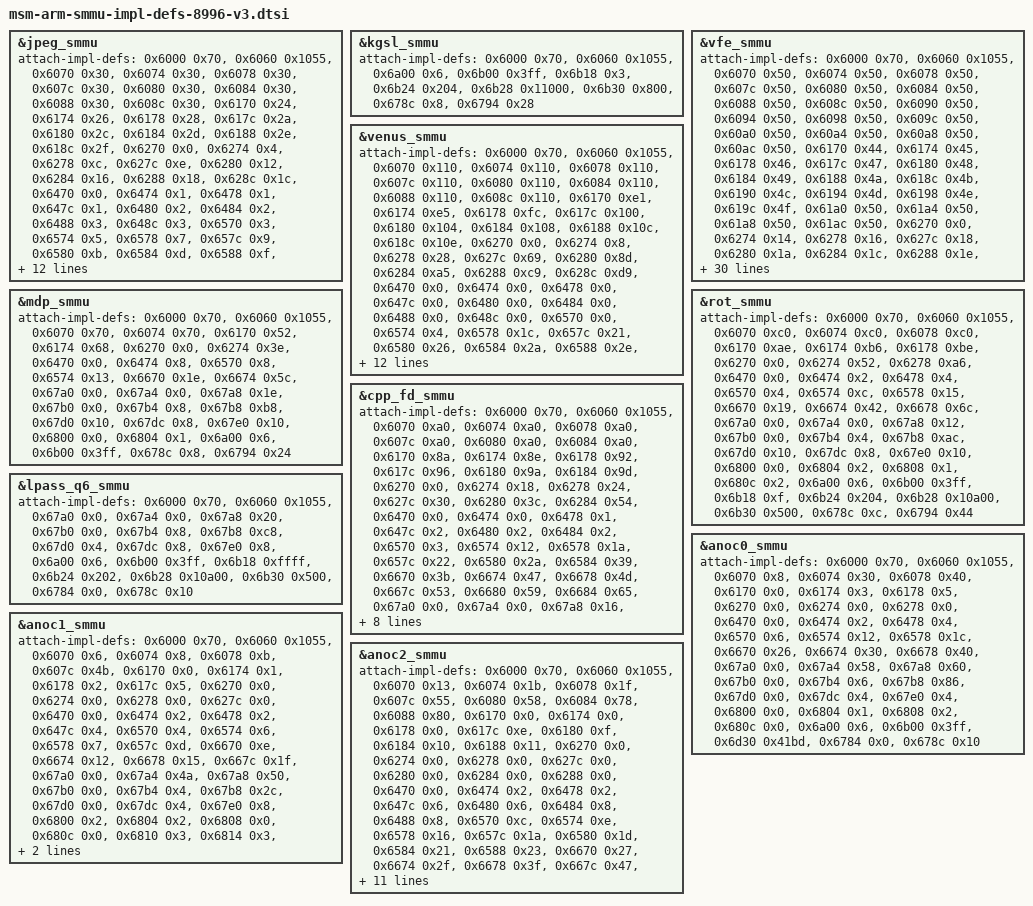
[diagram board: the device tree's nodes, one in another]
/* Copyright (c) 2015, The Linux Foundation. All rights reserved.
 *
 * This program is free software; you can redistribute it and/or modify
 * it under the terms of the GNU General Public License version 2 and
 * only version 2 as published by the Free Software Foundation.
 *
 * This program is distributed in the hope that it will be useful,
 * but WITHOUT ANY WARRANTY; without even the implied warranty of
 * MERCHANTABILITY or FITNESS FOR A PARTICULAR PURPOSE.  See the
 * GNU General Public License for more details.
 */


&jpeg_smmu {
	attach-impl-defs = <0x6000 0x70>,
		<0x6060 0x1055>,
		<0x6070 0x30>,
		<0x6074 0x30>,
		<0x6078 0x30>,
		<0x607c 0x30>,
		<0x6080 0x30>,
		<0x6084 0x30>,
		<0x6088 0x30>,
		<0x608c 0x30>,
		<0x6170 0x24>,
		<0x6174 0x26>,
		<0x6178 0x28>,
		<0x617c 0x2a>,
		<0x6180 0x2c>,
		<0x6184 0x2d>,
		<0x6188 0x2e>,
		<0x618c 0x2f>,
		<0x6270 0x0>,
		<0x6274 0x4>,
		<0x6278 0xc>,
		<0x627c 0xe>,
		<0x6280 0x12>,
		<0x6284 0x16>,
		<0x6288 0x18>,
		<0x628c 0x1c>,
		<0x6470 0x0>,
		<0x6474 0x1>,
		<0x6478 0x1>,
		<0x647c 0x1>,
		<0x6480 0x2>,
		<0x6484 0x2>,
		<0x6488 0x3>,
		<0x648c 0x3>,
		<0x6570 0x3>,
		<0x6574 0x5>,
		<0x6578 0x7>,
		<0x657c 0x9>,
		<0x6580 0xb>,
		<0x6584 0xd>,
		<0x6588 0xf>,
		<0x658c 0x11>,
		<0x6670 0x13>,
		<0x6674 0x16>,
		<0x6678 0x1c>,
		<0x667c 0x1e>,
		<0x6680 0x21>,
		<0x6684 0x24>,
		<0x6688 0x26>,
		<0x668c 0x2a>,
		<0x67a0 0x0>,
		<0x67a4 0x0>,
		<0x67a8 0xc>,
		<0x67b0 0x0>,
		<0x67b4 0x3>,
		<0x67b8 0x83>,
		<0x67d0 0x10>,
		<0x67dc 0x8>,
		<0x67e0 0x10>,
		<0x6800 0x0>,
		<0x6804 0x1>,
		<0x6808 0x2>,
		<0x680c 0x3>,
		<0x6810 0x4>,
		<0x6814 0x5>,
		<0x6818 0x6>,
		<0x681c 0x7>,
		<0x6a00 0x6>,
		<0x6b00 0x3ff>,
		<0x6b18 0xff>,
		<0x6b24 0x204>,
		<0x6b28 0x10800>,
		<0x6b30 0x400>,
		<0x678c 0x6>,
		<0x6794 0x24>;
};

&kgsl_smmu {
	attach-impl-defs = <0x6000 0x70>,
		<0x6060 0x1055>,
		<0x6a00 0x6>,
		<0x6b00 0x3ff>,
		<0x6b18 0x3>,
		<0x6b24 0x204>,
		<0x6b28 0x11000>,
		<0x6b30 0x800>,
		<0x678c 0x8>,
		<0x6794 0x28>;
};

&vfe_smmu {
	attach-impl-defs = <0x6000 0x70>,
		<0x6060 0x1055>,
		<0x6070 0x50>,
		<0x6074 0x50>,
		<0x6078 0x50>,
		<0x607c 0x50>,
		<0x6080 0x50>,
		<0x6084 0x50>,
		<0x6088 0x50>,
		<0x608c 0x50>,
		<0x6090 0x50>,
		<0x6094 0x50>,
		<0x6098 0x50>,
		<0x609c 0x50>,
		<0x60a0 0x50>,
		<0x60a4 0x50>,
		<0x60a8 0x50>,
		<0x60ac 0x50>,
		<0x6170 0x44>,
		<0x6174 0x45>,
		<0x6178 0x46>,
		<0x617c 0x47>,
		<0x6180 0x48>,
		<0x6184 0x49>,
		<0x6188 0x4a>,
		<0x618c 0x4b>,
		<0x6190 0x4c>,
		<0x6194 0x4d>,
		<0x6198 0x4e>,
		<0x619c 0x4f>,
		<0x61a0 0x50>,
		<0x61a4 0x50>,
		<0x61a8 0x50>,
		<0x61ac 0x50>,
		<0x6270 0x0>,
		<0x6274 0x14>,
		<0x6278 0x16>,
		<0x627c 0x18>,
		<0x6280 0x1a>,
		<0x6284 0x1c>,
		<0x6288 0x1e>,
		<0x628c 0x20>,
		<0x6290 0x22>,
		<0x6294 0x36>,
		<0x6298 0x38>,
		<0x629c 0x3a>,
		<0x62a0 0x3c>,
		<0x62a4 0x3e>,
		<0x62a8 0x40>,
		<0x62ac 0x42>,
		<0x6470 0x0>,
		<0x6474 0x1>,
		<0x6478 0x2>,
		<0x647c 0x3>,
		<0x6480 0x4>,
		<0x6484 0x4>,
		<0x6488 0x4>,
		<0x648c 0x4>,
		<0x6490 0x4>,
		<0x6494 0x5>,
		<0x6498 0x6>,
		<0x649c 0x7>,
		<0x64a0 0x8>,
		<0x64a4 0x8>,
		<0x64a8 0x8>,
		<0x64ac 0x8>,
		<0x6570 0x8>,
		<0x6574 0xb>,
		<0x6578 0xe>,
		<0x657c 0x11>,
		<0x6580 0x13>,
		<0x6584 0x15>,
		<0x6588 0x17>,
		<0x658c 0x19>,
		<0x6590 0x1b>,
		<0x6594 0x1e>,
		<0x6598 0x21>,
		<0x659c 0x24>,
		<0x65a0 0x26>,
		<0x65a4 0x28>,
		<0x65a8 0x2a>,
		<0x65ac 0x2c>,
		<0x6670 0x2e>,
		<0x6674 0x38>,
		<0x6678 0x39>,
		<0x667c 0x3a>,
		<0x6680 0x3b>,
		<0x6684 0x3c>,
		<0x6688 0x3d>,
		<0x668c 0x3e>,
		<0x6690 0x3f>,
		<0x6694 0x49>,
		<0x6698 0x4a>,
		<0x669c 0x4b>,
		<0x66a0 0x4c>,
		<0x66a4 0x4d>,
		<0x66a8 0x4e>,
		<0x66ac 0x4f>,
		<0x67a0 0x0>,
		<0x67a4 0x0>,
		<0x67a8 0xc>,
		<0x67b0 0x0>,
		<0x67b4 0x8>,
		<0x67b8 0x138>,
		<0x67d0 0x10>,
		<0x67dc 0x8>,
		<0x67e0 0x10>,
		<0x6800 0x0>,
		<0x6804 0x1>,
		<0x6808 0x2>,
		<0x680c 0x3>,
		<0x6810 0x4>,
		<0x6814 0x5>,
		<0x6818 0x6>,
		<0x681c 0x7>,
		<0x6820 0x8>,
		<0x6824 0x9>,
		<0x6828 0xa>,
		<0x682c 0xb>,
		<0x6830 0xc>,
		<0x6834 0xd>,
		<0x6838 0xe>,
		<0x683c 0xf>,
		<0x6a00 0x6>,
		<0x6b00 0x3ff>,
		<0x6b18 0xffff>,
		<0x6b24 0x204>,
		<0x6b28 0x10a00>,
		<0x6b30 0x500>,
		<0x678c 0xb>,
		<0x6794 0x2f>;
};

&venus_smmu {
	attach-impl-defs = <0x6000 0x70>,
		<0x6060 0x1055>,
		<0x6070 0x110>,
		<0x6074 0x110>,
		<0x6078 0x110>,
		<0x607c 0x110>,
		<0x6080 0x110>,
		<0x6084 0x110>,
		<0x6088 0x110>,
		<0x608c 0x110>,
		<0x6170 0xe1>,
		<0x6174 0xe5>,
		<0x6178 0xfc>,
		<0x617c 0x100>,
		<0x6180 0x104>,
		<0x6184 0x108>,
		<0x6188 0x10c>,
		<0x618c 0x10e>,
		<0x6270 0x0>,
		<0x6274 0x8>,
		<0x6278 0x28>,
		<0x627c 0x69>,
		<0x6280 0x8d>,
		<0x6284 0xa5>,
		<0x6288 0xc9>,
		<0x628c 0xd9>,
		<0x6470 0x0>,
		<0x6474 0x0>,
		<0x6478 0x0>,
		<0x647c 0x0>,
		<0x6480 0x0>,
		<0x6484 0x0>,
		<0x6488 0x0>,
		<0x648c 0x0>,
		<0x6570 0x0>,
		<0x6574 0x4>,
		<0x6578 0x1c>,
		<0x657c 0x21>,
		<0x6580 0x26>,
		<0x6584 0x2a>,
		<0x6588 0x2e>,
		<0x658c 0x30>,
		<0x6670 0x32>,
		<0x6674 0x36>,
		<0x6678 0x46>,
		<0x667c 0x58>,
		<0x6680 0x62>,
		<0x6684 0x6d>,
		<0x6688 0x75>,
		<0x668c 0x7d>,
		<0x67a0 0x0>,
		<0x67a4 0x0>,
		<0x67a8 0x2f>,
		<0x67b0 0x0>,
		<0x67b4 0x0>,
		<0x67b8 0x190>,
		<0x67d0 0x8>,
		<0x67dc 0x8>,
		<0x67e0 0x8>,
		<0x6800 0x0>,
		<0x6804 0x1>,
		<0x6808 0x2>,
		<0x680c 0x3>,
		<0x6810 0x4>,
		<0x6814 0x5>,
		<0x6818 0x6>,
		<0x681c 0x7>,
		<0x6a00 0x6>,
		<0x6b00 0x3ff>,
		<0x6b18 0xff>,
		<0x6b24 0x203>,
		<0x6b28 0x10a00>,
		<0x6b30 0x500>,
		<0x678c 0x18>,
		<0x6794 0x43>;
};

&mdp_smmu {
	attach-impl-defs = <0x6000 0x70>,
		<0x6060 0x1055>,
		<0x6070 0x70>,
		<0x6074 0x70>,
		<0x6170 0x52>,
		<0x6174 0x68>,
		<0x6270 0x0>,
		<0x6274 0x3e>,
		<0x6470 0x0>,
		<0x6474 0x8>,
		<0x6570 0x8>,
		<0x6574 0x13>,
		<0x6670 0x1e>,
		<0x6674 0x5c>,
		<0x67a0 0x0>,
		<0x67a4 0x0>,
		<0x67a8 0x1e>,
		<0x67b0 0x0>,
		<0x67b4 0x8>,
		<0x67b8 0xb8>,
		<0x67d0 0x10>,
		<0x67dc 0x8>,
		<0x67e0 0x10>,
		<0x6800 0x0>,
		<0x6804 0x1>,
		<0x6a00 0x6>,
		<0x6b00 0x3ff>,
		<0x678c 0x8>,
		<0x6794 0x24>;
};

&rot_smmu {
	attach-impl-defs = <0x6000 0x70>,
		<0x6060 0x1055>,
		<0x6070 0xc0>,
		<0x6074 0xc0>,
		<0x6078 0xc0>,
		<0x6170 0xae>,
		<0x6174 0xb6>,
		<0x6178 0xbe>,
		<0x6270 0x0>,
		<0x6274 0x52>,
		<0x6278 0xa6>,
		<0x6470 0x0>,
		<0x6474 0x2>,
		<0x6478 0x4>,
		<0x6570 0x4>,
		<0x6574 0xc>,
		<0x6578 0x15>,
		<0x6670 0x19>,
		<0x6674 0x42>,
		<0x6678 0x6c>,
		<0x67a0 0x0>,
		<0x67a4 0x0>,
		<0x67a8 0x12>,
		<0x67b0 0x0>,
		<0x67b4 0x4>,
		<0x67b8 0xac>,
		<0x67d0 0x10>,
		<0x67dc 0x8>,
		<0x67e0 0x10>,
		<0x6800 0x0>,
		<0x6804 0x2>,
		<0x6808 0x1>,
		<0x680c 0x2>,
		<0x6a00 0x6>,
		<0x6b00 0x3ff>,
		<0x6b18 0xf>,
		<0x6b24 0x204>,
		<0x6b28 0x10a00>,
		<0x6b30 0x500>,
		<0x678c 0xc>,
		<0x6794 0x44>;
};

&cpp_fd_smmu {
	attach-impl-defs = <0x6000 0x70>,
		<0x6060 0x1055>,
		<0x6070 0xa0>,
		<0x6074 0xa0>,
		<0x6078 0xa0>,
		<0x607c 0xa0>,
		<0x6080 0xa0>,
		<0x6084 0xa0>,
		<0x6170 0x8a>,
		<0x6174 0x8e>,
		<0x6178 0x92>,
		<0x617c 0x96>,
		<0x6180 0x9a>,
		<0x6184 0x9d>,
		<0x6270 0x0>,
		<0x6274 0x18>,
		<0x6278 0x24>,
		<0x627c 0x30>,
		<0x6280 0x3c>,
		<0x6284 0x54>,
		<0x6470 0x0>,
		<0x6474 0x0>,
		<0x6478 0x1>,
		<0x647c 0x2>,
		<0x6480 0x2>,
		<0x6484 0x2>,
		<0x6570 0x3>,
		<0x6574 0x12>,
		<0x6578 0x1a>,
		<0x657c 0x22>,
		<0x6580 0x2a>,
		<0x6584 0x39>,
		<0x6670 0x3b>,
		<0x6674 0x47>,
		<0x6678 0x4d>,
		<0x667c 0x53>,
		<0x6680 0x59>,
		<0x6684 0x65>,
		<0x67a0 0x0>,
		<0x67a4 0x0>,
		<0x67a8 0x16>,
		<0x67b0 0x0>,
		<0x67b4 0x3>,
		<0x67b8 0x1c3>,
		<0x67d0 0x10>,
		<0x67dc 0x8>,
		<0x67e0 0x10>,
		<0x6800 0x0>,
		<0x6804 0x1>,
		<0x6808 0x2>,
		<0x680c 0x3>,
		<0x6810 0x4>,
		<0x6814 0x5>,
		<0x6818 0x0>,
		<0x681c 0x0>,
		<0x6a00 0x6>,
		<0x6b00 0x3ff>,
		<0x6b18 0xff>,
		<0x6b24 0x204>,
		<0x6b28 0x10a00>,
		<0x6b30 0x500>,
		<0x678c 0x8>,
		<0x6794 0x2f>;
};

&lpass_q6_smmu {
	attach-impl-defs = <0x6000 0x70>,
		<0x6060 0x1055>,
		<0x67a0 0x0>,
		<0x67a4 0x0>,
		<0x67a8 0x20>,
		<0x67b0 0x0>,
		<0x67b4 0x8>,
		<0x67b8 0xc8>,
		<0x67d0 0x4>,
		<0x67dc 0x8>,
		<0x67e0 0x8>,
		<0x6a00 0x6>,
		<0x6b00 0x3ff>,
		<0x6b18 0xffff>,
		<0x6b24 0x202>,
		<0x6b28 0x10a00>,
		<0x6b30 0x500>,
		<0x6784 0x0>,
		<0x678c 0x10>;
};

&anoc0_smmu {
	attach-impl-defs = <0x6000 0x70>,
		<0x6060 0x1055>,
		<0x6070 0x8>,
		<0x6074 0x30>,
		<0x6078 0x40>,
		<0x6170 0x0>,
		<0x6174 0x3>,
		<0x6178 0x5>,
		<0x6270 0x0>,
		<0x6274 0x0>,
		<0x6278 0x0>,
		<0x6470 0x0>,
		<0x6474 0x2>,
		<0x6478 0x4>,
		<0x6570 0x6>,
		<0x6574 0x12>,
		<0x6578 0x1c>,
		<0x6670 0x26>,
		<0x6674 0x30>,
		<0x6678 0x40>,
		<0x67a0 0x0>,
		<0x67a4 0x58>,
		<0x67a8 0x60>,
		<0x67b0 0x0>,
		<0x67b4 0x6>,
		<0x67b8 0x86>,
		<0x67d0 0x0>,
		<0x67dc 0x4>,
		<0x67e0 0x4>,
		<0x6800 0x0>,
		<0x6804 0x1>,
		<0x6808 0x2>,
		<0x680c 0x0>,
		<0x6a00 0x6>,
		<0x6b00 0x3ff>,
		<0x6d30 0x41bd>,
		<0x6784 0x0>,
		<0x678c 0x10>;
};

&anoc1_smmu {
	attach-impl-defs = <0x6000 0x70>,
		<0x6060 0x1055>,
		<0x6070 0x6>,
		<0x6074 0x8>,
		<0x6078 0xb>,
		<0x607c 0x4b>,
		<0x6170 0x0>,
		<0x6174 0x1>,
		<0x6178 0x2>,
		<0x617c 0x5>,
		<0x6270 0x0>,
		<0x6274 0x0>,
		<0x6278 0x0>,
		<0x627c 0x0>,
		<0x6470 0x0>,
		<0x6474 0x2>,
		<0x6478 0x2>,
		<0x647c 0x4>,
		<0x6570 0x4>,
		<0x6574 0x6>,
		<0x6578 0x7>,
		<0x657c 0xd>,
		<0x6670 0xe>,
		<0x6674 0x12>,
		<0x6678 0x15>,
		<0x667c 0x1f>,
		<0x67a0 0x0>,
		<0x67a4 0x4a>,
		<0x67a8 0x50>,
		<0x67b0 0x0>,
		<0x67b4 0x4>,
		<0x67b8 0x2c>,
		<0x67d0 0x0>,
		<0x67dc 0x4>,
		<0x67e0 0x8>,
		<0x6800 0x2>,
		<0x6804 0x2>,
		<0x6808 0x0>,
		<0x680c 0x0>,
		<0x6810 0x3>,
		<0x6814 0x3>,
		<0x6818 0x1>,
		<0x681c 0x0>,
		<0x6a00 0x6>,
		<0x6b00 0x3ff>,
		<0x6d30 0x41bd>;
};

&anoc2_smmu {
	attach-impl-defs = <0x6000 0x70>,
		<0x6060 0x1055>,
		<0x6070 0x13>,
		<0x6074 0x1b>,
		<0x6078 0x1f>,
		<0x607c 0x55>,
		<0x6080 0x58>,
		<0x6084 0x78>,
		<0x6088 0x80>,
		<0x6170 0x0>,
		<0x6174 0x0>,
		<0x6178 0x0>,
		<0x617c 0xe>,
		<0x6180 0xf>,
		<0x6184 0x10>,
		<0x6188 0x11>,
		<0x6270 0x0>,
		<0x6274 0x0>,
		<0x6278 0x0>,
		<0x627c 0x0>,
		<0x6280 0x0>,
		<0x6284 0x0>,
		<0x6288 0x0>,
		<0x6470 0x0>,
		<0x6474 0x2>,
		<0x6478 0x2>,
		<0x647c 0x6>,
		<0x6480 0x6>,
		<0x6484 0x8>,
		<0x6488 0x8>,
		<0x6570 0xc>,
		<0x6574 0xe>,
		<0x6578 0x16>,
		<0x657c 0x1a>,
		<0x6580 0x1d>,
		<0x6584 0x21>,
		<0x6588 0x23>,
		<0x6670 0x27>,
		<0x6674 0x2f>,
		<0x6678 0x3f>,
		<0x667c 0x47>,
		<0x6680 0x4c>,
		<0x6684 0x54>,
		<0x6688 0x58>,
		<0x67a0 0x0>,
		<0x67a4 0x8d>,
		<0x67a8 0xa0>,
		<0x67b0 0x0>,
		<0x67b4 0xc>,
		<0x67b8 0x78>,
		<0x67d0 0x0>,
		<0x67dc 0x4>,
		<0x67e0 0x8>,
		<0x6800 0x0>,
		<0x6804 0x0>,
		<0x6808 0x1>,
		<0x680c 0x1>,
		<0x6810 0x0>,
		<0x6814 0x0>,
		<0x6818 0x1>,
		<0x681c 0x1>,
		<0x6820 0x3>,
		<0x6824 0x2>,
		<0x6828 0x5>,
		<0x682c 0x4>,
		<0x6830 0x6>,
		<0x6834 0x6>,
		<0x6838 0x0>,
		<0x683c 0x0>,
		<0x6a00 0x6>,
		<0x6b00 0x3ff>,
		<0x6d30 0x41bd>,
		<0x678c 0xa>,
		<0x6794 0x1a>;
};
